# iND83213A register map
Vendor: Indiemicro; Series: Rugby; File version: 1.0
CPU: CM0 r0p1, selectable endian, no MPU, no FPU, 4 interrupt priority bits
Registers are 32-bit, read-write, no defined reset value unless marked. A register's access mark holds for its fields unless they carry their own. Offsets are from the block's base; [hi:lo] are bit positions.

## PMUA — Power Management Unit
Base 0x50000040; register names take the prefix PMUA_
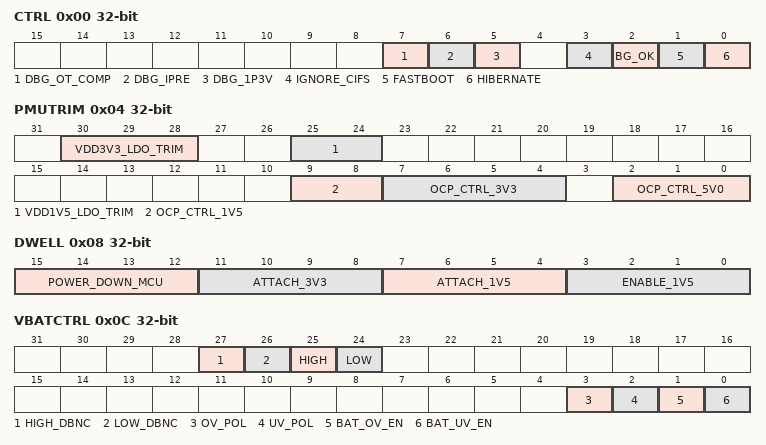
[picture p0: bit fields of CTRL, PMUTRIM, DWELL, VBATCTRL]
0x00 CTRL — Control
  [7] DBG_OT_COMP — Enable to test the comparator of over temperature function.
  [6] DBG_IPRE — EN test IBIAS_PRE 1uA current.
  [5] DBG_1P3V — LDO_1V5 output 1.35V, Set to 1V5-LDO output 1V35.
  [3] IGNORE_CIFS — Ignore QACKs. Setting a bit in this register prevents PMUA from waiting for the assertion of the corresponding 'Quiescent State Acknowlege' signal when before transitioning towards the Hibernate state.
  [2] BG_OK ro — the flag of bandgap OK. the flag of bandgap OK
  [1] FASTBOOT — Fast boot. Set to enable used of the fast clock during subsequent power-up sequences (including the portion consumed by the Clough boot sequence). The set value brings the system up with the slow clock to make the initial boot and any boot after a hard reset (e.g. after a brownout) as safe as possible.
  [0] HIBERNATE wo — Hibernate. Set to put the chip into HIBERATE mode. Before setting this bit, ensure that wake interrupt controller HOLD bit has been set (and that a corresponding Lullaby interrupt has been received).
0x04 PMUTRIM
  [30:28] VDD3V3_LDO_TRIM — 3.3V LDO output trim. at PMU debug mode 0x0: 3.00V 0x1: 3.09V 0x2: 3.18V 0x3: 3.28V 0x4: 3.40V (default) 0x5: 3.52V 0x6: 3.65V 0x7: 3.80V
  [25:24] VDD1V5_LDO_TRIM — 1.5V LDO output trim. at PMU debug mode 0x0: 1.500V 0x1: 1.545V(default) 0x2: 1.606V 0x3: 1.606V
  [9:8] OCP_CTRL_1V5 — OCP trim for 1.5V LDO(default 30mA). 0x0: 17 mA 0x1: 30 mA (default) 0x2: 46 mA 0x3: 60 mA
  [7:4] OCP_CTRL_3V3 — OCP trim for 3V3 LDO(default 30mA). 0x0: 9.5 mA 0x1: 11.8 mA 0x2: 14.0 mA 0x3: 16.5 mA 0x4: 18.8 mA 0x5: 21.2 mA 0x6: 23.6 mA 0x7: 26.0 mA 0x8: 28.3 mA 0x9: 30.0 mA (default) 0xa: 33.0 mA 0xb: 35.4 mA 0xc: 38.0 mA 0xd: 40.0 mA 0xe: 42.5 mA 0xf: 45.0 mA
  [2:0] OCP_CTRL_5V0 — OCP trim for 5V LDO(default 80mA). 0x0: 53 mA 0x1: 44 mA 0x2: 35 mA 0x3: 25 mA 0x4: 115 mA 0x5: 80 mA(default) 0x6: 72 mA 0x7: 62 mA
0x08 DWELL
  [15:12] POWER_DOWN_MCU — Power down MCU dwell time. Defines the amount of time spent in the 'Power down MCU' state. Pausing here allows the MCU supplies to discharge (to guarantee subsequent POR)
  [11:8] ATTACH_3V3 — Attach 3.3V dwell time. Defines the amount of time spent in the 'Attach 3V3' state. State Attaches 3.3V to MCU.
  [7:4] ATTACH_1V5 — Attach 1.5V dwell time. Defines the amount of time spent in the 'Attach 1V5' state. State Attaches 1.5V to MCU.
  [3:0] ENABLE_1V5 — Enable 1.5V dwell time. Defines the amount of time spent in the 'Enable 1V5' state. Allows 3v3 and 1v5 regs to settle
0x0C VBATCTRL — VBAT Monitor Register
  [27] HIGH_DBNC ro — Battery Voltage High Status after deboucing. Battery monitor over voltage event signal coming from the debouncer of analog comparator circuit.
  [26] LOW_DBNC ro — Battery Voltage Low Status after debouncing. Battery monitor under voltage event signal coming from the debouncer of analog comparator circuit.
  [25] HIGH ro — Battery Voltage High Status. RAW battery monitor over voltage event signal coming from the analog comparator circuit.
  [24] LOW ro — Battery Voltage Low Status. RAW battery monitor under voltage event signal coming from the analog comparator circuit.
  [3] OV_POL — Battery Voltage Monitor Over Voltage Interrupt Event Polarity. Flips the over voltage event signal coming from the analog comparator circuit which feeds into the interrupt generator. 0x0: Native Polarity 0x1: Flip Polarity
  [2] UV_POL — Battery Voltage Monitor Under Voltage Interrupt Event Polarity. Flips the under voltage event signal coming from the analog comparator circuit which feeds into the interrupt generator. 0x0: Native Polarity 0x1: Flip Polarity
  [1] BAT_OV_EN — Battery Over Voltage Monitor Enable. Set to enable the vbat over voltage monitor analog comparator circuit.
  [0] BAT_UV_EN — Battery Under Voltage Monitor Enable. Set to enable the vbat under voltage monitor analog comparator circuit.
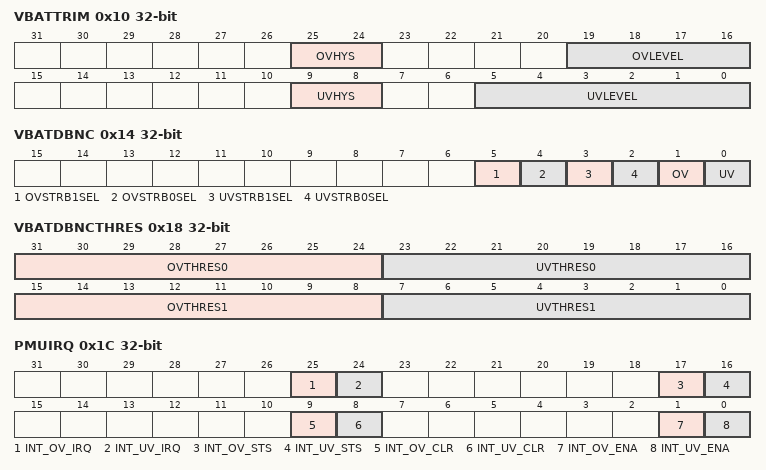
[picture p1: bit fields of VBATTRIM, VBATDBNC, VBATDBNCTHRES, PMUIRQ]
0x10 VBATTRIM — VBAT Monitor Trim Register
  [25:24] OVHYS — Battery Voltage Monitor Over Voltage Hysterisis Select. Selects the hysterisis level for the Over Voltage monitor. 0x0: 0.359V 0x1: 0.720V 0x2: 1.080V 0x3: 1.440V
  [19:16] OVLEVEL — Battery Voltage Monitor Over Voltage Select. Selects the reference level for the Over Voltage monitor to output one-hot Configuration to Analog Module.(If OVLEVEL>9, the actual analog trim value is the same as default value:OVLEVEL=0x07) 0x0: Over Voltage Threshold- 10'h001: 14.67V 0x1: Over Voltage Threshold- 10'h002: 15.16V 0x2: Over Voltage Threshold- 10'h004: 15.68V 0x3: Over Voltage Threshold- 10'h008: 16.23V 0x4: Over Voltage Threshold- 10'h010: 16.83V 0x5: Over Voltage Threshold- 10'h020: 17.48V 0x6: Over Voltage Threshold- 10'h040: 18.17V 0x7: Over Voltage Threshold- 10'h080: 18.93V(default) 0x8: Over Voltage Threshold- 10'h100: 19.75V 0x9: Over Voltage Threshold- 10'h200: 20.64V
  [9:8] UVHYS — Battery Voltage Monitor Under Voltage Hysterisis Select. Selects the hysterisis level for the Under Voltage monitor. 0x0: 0.475V 0x1: 0.835V 0x2: 1.225V 0x3: 1.635V
  [5:0] UVLEVEL — Battery Voltage Monitor Under Voltage Select. Selects the reference level for the Under Voltage monitor. If UVLEVEL[5:3]>0x04, the actual analog trim value is the same as UVLEVEL=0x0A. The UVLEVEL threshold is mononically increased with the setting. 0x0: Vf: 4.615V 0x1: Vf: 4.685V 0x7: Vf: 5.135V 0x8: Vf: 5.225V 0x9: Vf: 5.135V 0xa: Vf: 5.405V(default) 0xf: Vf: 5.895V 0x10: Vf: 6.015V 0x11: Vf: 6.125V 0x17: Vf: 6.925V 0x18: Vf: 7.075V 0x19: Vf: 7.235V 0x1f: Vf: 8.385V 0x20: Vf: 8.605V 0x21: Vf: 8.845V 0x27: Vf:10.610V
0x14 VBATDBNC — VBAT Debounce Register
  [5] OVSTRB1SEL — Low frequency strobing select for debouncing. Enables strobing 1 with the Low frequency clock(16K) instead of just clocking with High frequency Clock(16M). Default is set to 0 for quick acknowledgement of OV event.
  [4] OVSTRB0SEL — Low frequency strobing select for debouncing. Enables strobing 0 with the Low frequency clock(16K) instead of just clocking with High frequency Clock(16M). Default is set to 1 for debouncing of OV.
  [3] UVSTRB1SEL — Low frequency strobing select for debouncing. Enables strobing 1 with the Low frequency clock(16K) instead of just clocking with High frequency Clock(16M). Default is set to 0 for quick acknowledgement of UV event.
  [2] UVSTRB0SEL — Low frequency strobing select for debouncing. Enables strobing 0 with the Low frequency clock(16K) instead of just clocking with High frequency Clock(16M). Default is set to 1 for debouncing of UV.
  [1] OV — over voltage signal debounce enable. if set to '1, debounces the over voltage signal before going to over voltage interrupt generation else the signal bypass the debouncer
  [0] UV — under voltage signal debounce enable. if set to '1, debounces the under voltage signal before going to under voltage interrupt generation else the signal bypass the debouncer
0x18 VBATDBNCTHRES — VBAT Monitor Threshold Register
  [31:24] OVTHRES0 — Over Voltage debouncing threshold for 1to0 Transition. Sets the threshold for debouncing the over voltage event going from 1 to 0. It will require the ov event to stay high for the (OVTHRES0+1) number of LF/HF clocks to transit from a 1 to 0.
  [23:16] UVTHRES0 — Under Voltage debouncing threshold for 1to0 Transition. Sets the threshold for debouncing the under voltage event going from 1 to 0. It will require the uv event to stay high for the (UVTHRES0+1) number of LF/HF clocks to transit from a 1 to 0.
  [15:8] OVTHRES1 — Over Voltage debouncing threshold for 0to1 Transition. Sets the threshold for debouncing the over voltage event going from 0 to 1. It will require the ov event to stay high for the (OVTHRES1+1) number of LF/HF clocks to transit from a 0 to 1.
  [7:0] UVTHRES1 — Under Voltage debouncing threshold for 0to1 Transition. Sets the threshold for debouncing the under voltage event going from 0 to 1. It will require the uv event to stay high for the (UVTHRES1+1) number of LF/HF clocks to transit from a 0 to 1.
0x1C PMUIRQ — Voltage Monitor interrupts
  [25] INT_OV_IRQ ro — over voltage interrupt active.
  [24] INT_UV_IRQ ro — under voltage interrupt active.
  [17] INT_OV_STS ro — over voltage interrupt status.
  [16] INT_UV_STS ro — under voltage interrupt status.
  [9] INT_OV_CLR wo — over voltage interrupt clear. Autoclear: includes a synchronous reset signal which clears the register on the cycle following write.
  [8] INT_UV_CLR wo — under voltage interrupt clear. Autoclear: includes a synchronous reset signal which clears the register on the cycle following write.
  [1] INT_OV_ENA — over voltage interrupt enable.
  [0] INT_UV_ENA — under voltage interrupt enable.
